# M55M1 register map
File version: 1.0
Registers are 32-bit, read-write, reset 0x0 unless marked. A register's access mark holds for its fields unless they carry their own. Offsets are from the block's base; [hi:lo] are bit positions.

## VAD_NS — DMIC Register Map
Base 0x50445300
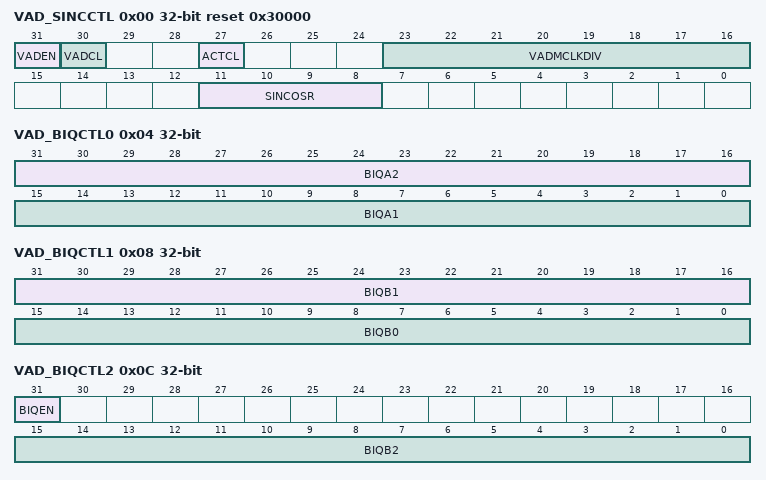
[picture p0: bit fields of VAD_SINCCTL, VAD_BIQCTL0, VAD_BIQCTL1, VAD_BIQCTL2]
0x00 VAD_SINCCTL reset 0x30000 — VAD SINC Filter Control Register
  [31] VADEN — VAD Enable Control. Note 1: When setting this bit to 1 and not active in DMIC mode, DMIC_CLK is generated by VAD module. Note 2: When active in DMIC mode, suggest to disable this bit.
    0=VAD mode, VAD interrupt and ACTIVE(VAD_STATUS0[31]) flag Disabled; 1=VAD mode, VAD interrupt and ACTIVE(VAD_STATUS0[31]) flag Enabled
  [30] VADCL — VAD Clear. Note: ACTIVE(VAD_STATUS0[31]), STP(VAD_STATUS0[15:0], LTP(VAD_STATUS1[31:16], DEV(VAD_STATUS1[15:0]) are cleared.
    0=No effect; 1=Reset VAD
  [27] ACTCL — VAD Active Flag Clear
    0=No effect; 1=Clear ACTIVE(VAD_STATUS0[31])
  [23:16] VADMCLKDIV — Divider to generate the VAD Working Main Clock. The value in this field is the frequency divider for generating the DMIC working main clock. The frequency is obtained according to the following equation. where F_VAD_CLK_SRC is the frequency of DMIC module clock source, which is defined in the clock control register DMICSEL VAD0SEL (CLK_DMICSEL [5:4]) and F_DMIC_MCLK depends on the cycle of DMIC DSP processor needed.
  [11:8] SINCOSR — VAD SINC Filter OSR Setting
    0=Down sample 48; 1=Down sample 64; 2=Down sample 96
0x04 VAD_BIQCTL0 — VAD Biquad Filter Control Register 0
  [31:16] BIQA2 — VAD Biquad Filter Coefficient. Biquad Filter Coefficient a2, in 3 intergers + 13 fractional bits. VAD_BIQCTL0[31] and VAD_BIQCTL0[16] correspond to MSB and LSB respectively.
  [15:0] BIQA1 — VAD Biquad Filter Coefficient. Biquad Filter Coefficient a1, in 3 intergers + 13 fractional bits. VAD_BIQCTL0[15] and VAD_BIQCTL0[0] correspond to MSB and LSB respectively.
0x08 VAD_BIQCTL1 — VAD Biquad Filter Control Register 1
  [31:16] BIQB1 — VAD Biquad Filter Coefficient. Biquad Filter Coefficient a2, in 3 intergers + 13 fractional bits. VAD_BIQCTL1[31] and VAD_BIQCTL1[16] correspond to MSB and LSB respectively.
  [15:0] BIQB0 — VAD Biquad Filter Coefficient. Biquad Filter Coefficient a1, in 3 intergers + 13 fractional bits. VAD_BIQCTL1[15] and VAD_BIQCTL1[0] correspond to MSB and LSB respectively.
0x0C VAD_BIQCTL2 — VAD Biquad Filter Control Register 2
  [31] BIQEN — VAD Biquad Filter Enable Bit
    0=VAD Biquad Filter Disabled; 1=VAD Biquad Filter Enabled
  [15:0] BIQB2 — VAD Biquad Filter Coefficient. Biquad Filter Coefficient a1, in 3 intergers + 13 fractional bits. VAD_BIQCTL2[15] and VAD_BIQCTL2[0] correspond to MSB and LSB respectively.
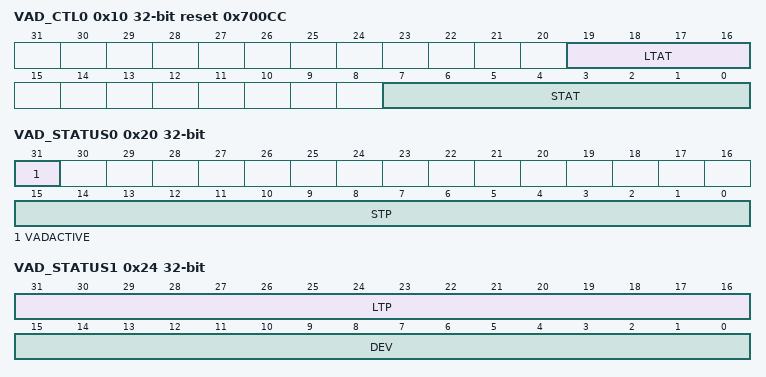
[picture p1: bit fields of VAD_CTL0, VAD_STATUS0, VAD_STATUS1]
0x10 VAD_CTL0 reset 0x700CC — VAD Control Register 0
  [19:16] LTAT — Long Term Power Attack Time. Slow attack (e.g., 0x5): less sensitive to environment change. Fast attack (e.g., 0x8): more sensitive to environment change.
  [7:0] STAT — Short Term Power Attack Time. Slow attack (e.g., 0x99): slow responding to voice, but more stable. Fast attack (e.g., 0xCC): fast responding to voice, but more sensitive to other sounds. Suggested default attack time setting: Long term power attack time (0x5), Short term power attack time (0xAA). The 'Short Term Power', in order to detect the instant power of the voices, requires faster attack time, while 'Long Term Power', in order to get the averaged power of the background environment, requires slower attack time to maintain its stability. So the Short term power attack time should be always bigger than the Long term power attack time.
0x14 VAD_CTL1 reset 0x7FFF — VAD Control Register 1
  [15:0] STTHREHWM — Short Term Power Threshold Upper Limit. Refer to the value of STP (VAD_STATUS0[15:0]). To check if the incoming signal is big enough to be ready for VAD activation.
0x18 VAD_CTL2 — VAD Control Register 2
  [31:16] LTTHRE — Long Term Power Threshold. Refer to the value of LTP (VAD_STATUS1[31:16]). To check the background energy, also serve as the lower limit of long term power. When the long term power value is lower than the threshold, it will be set to the threshold value for VAD decision.
0x1C VAD_CTL3 reset 0x7FFF — VAD Control Register 3
  [15:0] DEVTHRE — Deviation Threshold. Refer to the value of DEV (VAD_STATUS1[15:0]). To check if the incoming signal is substantially bigger than its background. This may work to exclude breath sound as it is slowly varying, but not other sounds (e.g., footsteps, hand claps) with sudden amplitude increase. Small: easy to trigger, good for far-field pick-up, but requiring quiet environment. Large: good for handheld applications, but requiring louder voice to trigger.
0x20 VAD_STATUS0 ro — VAD Status Read-back Register 0
  [31] VADACTIVE — VAD Activation Interrupt (Read Only). When the matching voice is detected event occurs, this bit will be set to 1.
    0=No effect; 1=Voice detected
  [15:0] STP — Short Term Signal Power (Read Only). This field shows the short term signal power value.
0x24 VAD_STATUS1 ro — VAD Status Read-back Register 1
  [31:16] LTP — Long Term Signal Power (Read Only). This field shows the long term signal power value.
  [15:0] DEV — Deviation (Read Only). This field shows deviation of the Long Term Signal Power and Short Term Signal Power.
